# PIC32CM6408PL10028 device description
Architecture: CORTEX-M0PLUS; Family: PIC32CMPL; Series: PIC32CMPL10
Registers are 32-bit, read-write, reset 0x0 unless marked. A register's access mark holds for its fields unless they carry their own. Offsets are from the block's base; [hi:lo] are bit positions; {n}, {i} and the like mark numbered series; 'fields as' and 'values as' point back to an identical list.

## OSC32KCTRL — 32.768 kHz Oscillators Controller
Instances: OSC32KCTRL 0x40001400
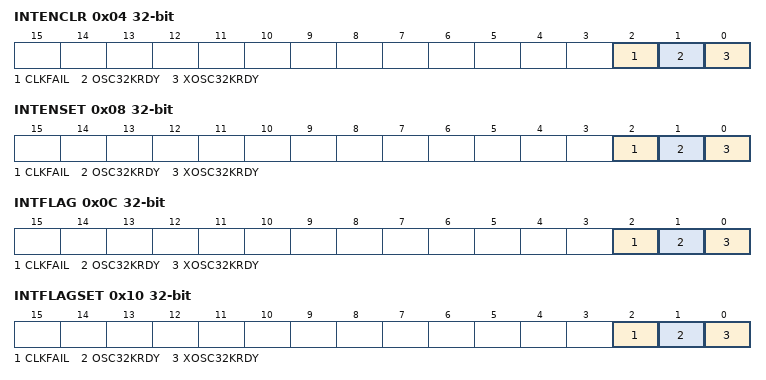
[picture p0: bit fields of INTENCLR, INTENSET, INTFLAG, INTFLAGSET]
0x04 INTENCLR (atomic clear) — Interrupt Enable Clear
  [2] CLKFAIL — XOSC32K Clock Failure Detection Interrupt Enable
  [1] OSC32KRDY — OSC32K Ready Interrupt Enable
  [0] XOSC32KRDY — XOSC32K Ready Interrupt Enable
0x08 INTENSET (atomic set) — Interrupt Enable Set
  fields as INTENCLR
0x0C INTFLAG (atomic clear) — Interrupt Flag Status and Clear
  [2] CLKFAIL — XOSC32K Clock Failure Detected
  [1] OSC32KRDY — OSC32K Ready
  [0] XOSC32KRDY — XOSC32K Ready
0x10 INTFLAGSET (atomic clear) — Interrupt Flag Software Set
  fields as INTFLAG
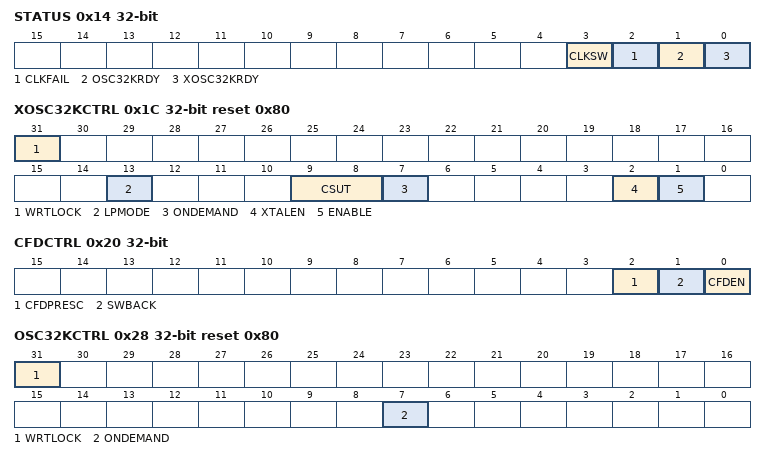
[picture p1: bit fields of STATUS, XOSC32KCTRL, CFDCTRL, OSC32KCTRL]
0x14 STATUS ro
  [3] CLKSW — XOSC32K Clock Switch
  [2] CLKFAIL — XOSC32K Clock Failure Detected
  [1] OSC32KRDY — OSC32K Ready
  [0] XOSC32KRDY — XOSC32K Ready
0x18 RTCCTRL — RTC Control
  [2:0] RTCSEL — RTC Clock Source Selection
    2=OSC1K (1.024 kHz from the internal 32.768 kHz oscillator); 3=OSC32K (32.768 kHz from the internal 32.768 kHz oscillator); 4=XOSC1K (1.024 kHz from the external 32.768 kHz crystal oscillator); 5=XOSC32K (32.768 kHz from the external 32.768 kHz crystal oscillator)
0x1C XOSC32KCTRL reset 0x80 — XOSC32K Control
  [31] WRTLOCK — Write Lock
  [13] LPMODE — Low Power Mode
  [9:8] CSUT — Crystal Oscillator Start-Up Time
    0=1K (1K XOSC32K cycles); 1=16K (16K XOSC32K cycles); 2=32K (32K XOSC32K cycles); 3=64K (64K XOSC32K cycles)
  [7] ONDEMAND — On-Demand Operation
  [2] XTALEN — External Source Select
    0=EXTCLK (External Clock on the XTAL32K1 pin. XTAL32K2 is available for other functions. The CSUT timer is disregarded, and no start-up time is used.); 1=XTAL (External Crystal connected to the XTAL32K1 and XTAL32K2 pins)
  [1] ENABLE — Oscillator Enable
0x20 CFDCTRL — Clock Failure Detector Control
  [2] CFDPRESC — Clock Failure Detector Prescaler
  [1] SWBACK — Clock Switch Back Enable
  [0] CFDEN — Clock Failure Detector Enable
0x24 EVCTRL — Event Control
  [0] CFDEO — Clock Failure Detector Event Output Enable
0x28 OSC32KCTRL reset 0x80 — 32.768 kHz Internal Oscillator (OSC32K) Control
  [31] WRTLOCK — Write Lock
  [7] ONDEMAND — On-Demand Operation
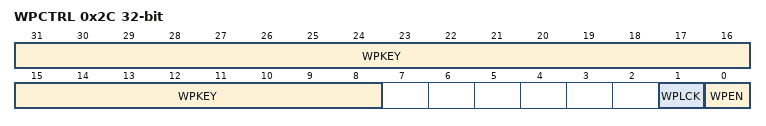
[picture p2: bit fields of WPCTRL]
0x2C WPCTRL — Write Protection Control
  [31:8] WPKEY — Write Protection Key
    0x4F5343=KEY (Allow writes to the WPCTRL register)
  [1] WPLCK — Write Protection Lock
  [0] WPEN — Write Protection Enable

## OSCCTRL — Oscillators Controller
Instances: OSCCTRL 0x40001000
0x04 INTENCLR (atomic clear) — Interrupt Enable Clear
  [4] OSCHFRDY — OSCHF Ready Interrupt Enable
0x08 INTENSET (atomic set) — Interrupt Enable Set
  [4] OSCHFRDY — OSCHF Ready Interrupt Enable
0x0C INTFLAG (atomic clear) — Interrupt Flag Status and Clear
  [4] OSCHFRDY — OSCHF is Ready
0x10 INTFLAGSET (atomic clear) — Interrupt Flag Software Set
  [4] OSCHFRDY — OSCHF is Ready
0x14 STATUS ro
  [4] OSCHFRDY — OSCHF is Ready
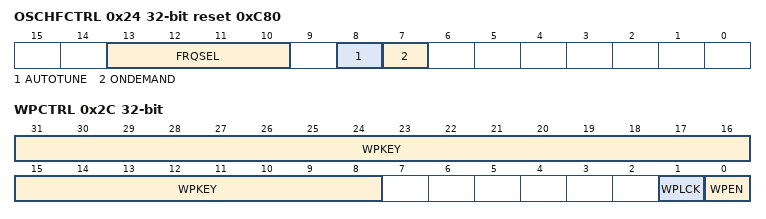
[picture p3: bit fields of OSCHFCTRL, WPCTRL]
0x24 OSCHFCTRL reset 0xC80 — OSCHF Control
  [13:10] FRQSEL — Frequency Select
    {v}={v+1}M ({v+1} MHz output clock) (v=0..3); 5=8M (8 MHz output clock); 6=12M (12 MHz output clock); 7=16M (16 MHz output clock); 8=20M (20 MHz output clock); 9=24M (24 MHz output clock)
  [8] AUTOTUNE — Automatic oscillator tune
    0=OFF (Automatic oscillator frequency tune disabled); 1=ON (Automatic oscillator frequency tune enabled)
  [7] ONDEMAND — On-Demand Operation
0x28 OSCHFTUNE — OSCHF Oscillator Frequency Tune
  [7:0] TUNE — Oscillator Tune
0x2C WPCTRL — Write Protection Control
  [31:8] WPKEY — Write Protection Key
    0x4F5343=KEY (Allow writes to the WPCTRL register)
  [1] WPLCK — Write Protection Lock
  [0] WPEN — Write Protection Enable

## PAC — Peripheral Access Controller
Instances: PAC 0x40000000
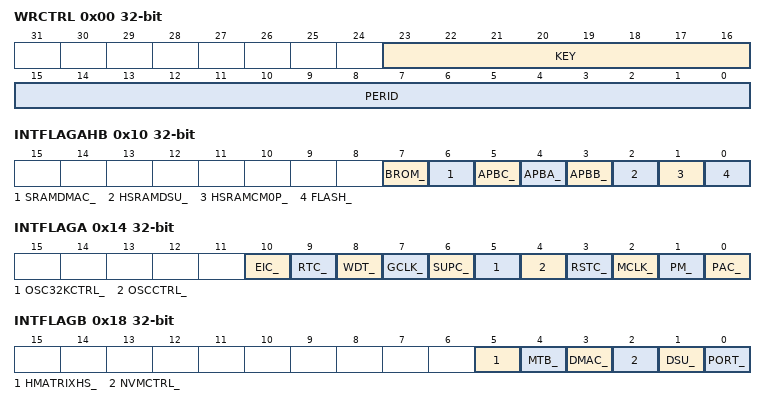
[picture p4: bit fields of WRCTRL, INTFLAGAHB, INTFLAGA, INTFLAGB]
0x00 WRCTRL — Write Control
  [23:16] KEY — Peripheral Access Control Key
    0=OFF (No action); 1=CLR (Clear the peripheral write-control); 2=SET (Set the peripheral write-control); 3=SETLCK (Set and lock the peripheral write-control until the next hardware reset)
  [15:0] PERID — Peripheral Identifier
    0=PAC (APBA Peripheral); 1=PM (APBA Peripheral); 2=MCLK (APBA Peripheral); 3=RSTC (APBA Peripheral); 4=OSCCTRL (APBA Peripheral); 5=OSC32KCTRL (APBA Peripheral); 6=SUPC (APBA Peripheral); 7=GCLK (APBA Peripheral); 8=WDT (APBA Peripheral); 9=RTC (APBA Peripheral); 10=EIC (APBA Peripheral); 32=PORT (APBB Peripheral); 33=DSU (APBB Peripheral); 34=NVMCTRL (APBB Peripheral); 35=DMAC (APBB Peripheral); 36=MTB (APBB Peripheral); 37=HMATRIXHS (APBB Peripheral); 64=EVSYS (APBC Peripheral); 65=SERCOM0 (APBC Peripheral); 66=SERCOM1 (APBC Peripheral); 67=TC0 (APBC Peripheral); 68=TC1 (APBC Peripheral); 69=TC2 (APBC Peripheral); 70=TCC0 (APBC Peripheral); 71=ADC0 (APBC Peripheral); 72=AC (APBC Peripheral); 73=CCL (APBC Peripheral); 74=PTC (APBC Peripheral); 75=SYSCTRL (APBC Peripheral)
0x04 EVCTRL 8-bit — Event Control
  [0] ERREO — Peripheral Access Error Event Output
0x08 INTENCLR 8-bit (atomic clear) — Interrupt Enable Clear
  [0] ERR — Peripheral Access Error Interrupt Disable
0x09 INTENSET 8-bit (atomic set) — Interrupt Enable Set
  [0] ERR — Peripheral Access Error Interrupt Enable
0x10 INTFLAGAHB (atomic clear) — AHB Client Bus Interrupt Flag Status and Clear
  [7] BROM_, [6] SRAMDMAC_, [5] APBC_, [4] APBA_, [3] APBB_, [2] HSRAMDSU_, [1] HSRAMCM0P_, [0] FLASH_
0x14 INTFLAGA (atomic clear) — Peripheral Interrupt Flag Status and Clear A
  [10] EIC_, [9] RTC_, [8] WDT_, [7] GCLK_, [6] SUPC_, [5] OSC32KCTRL_, [4] OSCCTRL_, [3] RSTC_, [2] MCLK_, [1] PM_, [0] PAC_
0x18 INTFLAGB (atomic clear) — Peripheral Interrupt Flag Status and Clear B
  [5] HMATRIXHS_, [4] MTB_, [3] DMAC_, [2] NVMCTRL_, [1] DSU_, [0] PORT_
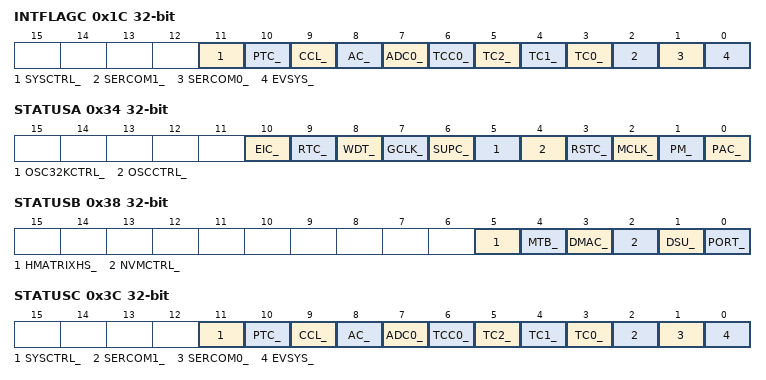
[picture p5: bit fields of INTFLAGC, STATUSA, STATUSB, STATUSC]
0x1C INTFLAGC (atomic clear) — Peripheral Interrupt Flag Status and Clear C
  [11] SYSCTRL_, [10] PTC_, [9] CCL_, [8] AC_, [7] ADC0_, [6] TCC0_, [5] TC2_, [4] TC1_, [3] TC0_, [2] SERCOM1_, [1] SERCOM0_, [0] EVSYS_
0x34 STATUSA ro — Peripheral Write Protection Status A
  [10] EIC_ — EIC APB Protect Enable
  [9] RTC_ — RTC APB Protect Enable
  [8] WDT_ — WDT APB Protect Enable
  [7] GCLK_ — GCLK APB Protect Enable
  [6] SUPC_ — SUPC APB Protect Enable
  [5] OSC32KCTRL_ — OSC32KCTRL APB Protect Enable
  [4] OSCCTRL_ — OSCCTRL APB Protect Enable
  [3] RSTC_ — RSTC APB Protect Enable
  [2] MCLK_ — MCLK APB Protect Enable
  [1] PM_ — PM APB Protect Enable
  [0] PAC_ — PAC APB Protect Enable
0x38 STATUSB ro — Peripheral Write Protection Status B
  [5] HMATRIXHS_ — HMATRIXHS APB Protect Enable
  [4] MTB_ — MTB APB Protect Enable
  [3] DMAC_ — DMAC APB Protect Enable
  [2] NVMCTRL_ — NVMCTRL APB Protect Enable
  [1] DSU_ — DSU APB Protect Enable
  [0] PORT_ — PORT APB Protect Enable
0x3C STATUSC ro — Peripheral Write Protection Status C
  [11] SYSCTRL_ — SYSCTRL APB Protect Enable
  [10] PTC_ — PTC APB Protect Enable
  [9] CCL_ — CCL APB Protect Enable
  [8] AC_ — AC APB Protect Enable
  [7] ADC0_ — ADC0 APB Protect Enable
  [6] TCC0_ — TCC0 APB Protect Enable
  [5] TC2_ — TC2 APB Protect Enable
  [4] TC1_ — TC1 APB Protect Enable
  [3] TC0_ — TC0 APB Protect Enable
  [2] SERCOM1_ — SERCOM1 APB Protect Enable
  [1] SERCOM0_ — SERCOM0 APB Protect Enable
  [0] EVSYS_ — EVSYS APB Protect Enable
